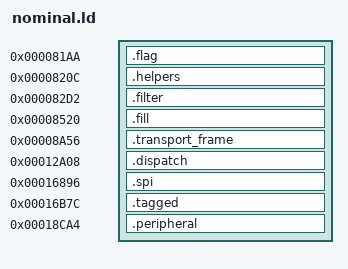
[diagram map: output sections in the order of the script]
OUTPUT_ARCH(riscv)
ENTRY(tsl9_queue_external_82d2)
SECTIONS {
  .flag 0x81aa : ALIGN(2) {
    KEEP(*(.text.tsl9_queue_external_81aa))
  }
  .helpers 0x820c : ALIGN(2) {
    KEEP(*(.text.tsl9_queue_external_820c))
    KEEP(*(.text.tsl9_dispatch_external_821e))
  }
  .filter 0x82d2 : ALIGN(2) {
    KEEP(*(.text.tsl9_queue_external_82d2))
    KEEP(*(.text.tsl9_filter_scan_8308))
    KEEP(*(.text.tsl9_filter_pack_8328))
    KEEP(*(.text.tsl9_filter_emit_8358))
    KEEP(*(.text.tsl9_filter_test_836a))
    KEEP(*(.text.tsl9_filter_finish_836e))
    KEEP(*(.text.tsl9_filter_second_838a))
  }
  .fill 0x8520 : ALIGN(2) {
    KEEP(*(.text.tsl9_tagged_external_8520))
    KEEP(*(.text.tsl9_fill_alignment_8528))
    KEEP(*(.text.tsl9_fill_pattern_guard_852e))
    KEEP(*(.text.tsl9_fill_word_setup_8530))
    KEEP(*(.text.tsl9_fill_words_8538))
    KEEP(*(.text.tsl9_fill_tail_guard_8546))
    KEEP(*(.text.tsl9_fill_word_return_8548))
    KEEP(*(.text.tsl9_fill_tail_dispatch_854a))
    KEEP(*(.text.tsl9_fill_bytes_855a))
    KEEP(*(.text.tsl9_fill_byte_return_8596))
    KEEP(*(.text.tsl9_fill_pattern_8598))
    KEEP(*(.text.tsl9_fill_align_dispatch_85aa))
    KEEP(*(.text.tsl9_fill_align_resume_85ba))
  }
  .transport_frame 0x8a56 : ALIGN(2) {
    KEEP(*(.text.tsl9_filter_external_8a56))
    KEEP(*(.text.tsl9_transport_frame_8a5e))
    KEEP(*(.text.tsl9_transport_first_8a7a))
    KEEP(*(.text.tsl9_transport_first_result_8a90))
    KEEP(*(.text.tsl9_transport_second_8a96))
    KEEP(*(.text.tsl9_transport_second_result_8ab6))
    KEEP(*(.text.tsl9_transport_reject_8abe))
    KEEP(*(.text.tsl9_transport_select0_8acc))
    KEEP(*(.text.tsl9_transport_pack_8ace))
    KEEP(*(.text.tsl9_transport_test_8b0a))
    KEEP(*(.text.tsl9_transport_finish_8b14))
    KEEP(*(.text.tsl9_transport_copy_8b52))
    KEEP(*(.text.tsl9_transport_bare_return_8b6c))
  }
  .dispatch 0x12a08 : ALIGN(2) {
    KEEP(*(.text.tsl9_queue_external_12a08))
    KEEP(*(.text.tsl9_dispatch_status_12a14))
    KEEP(*(.text.tsl9_dispatch_ID_12a16))
    KEEP(*(.text.tsl9_dispatch_query_12a20))
    KEEP(*(.text.tsl9_dispatch_tag_12a28))
    KEEP(*(.text.tsl9_dispatch_copy_12a2e))
    KEEP(*(.text.tsl9_dispatch_peripheral_12a50))
    KEEP(*(.text.tsl9_dispatch_finish_12a5e))
    KEEP(*(.text.tsl9_dispatch_tagged_12a66))
  }
  .spi 0x16896 : ALIGN(2) {
    KEEP(*(.text.tsl9_spi_transfer_entry_16896))
    KEEP(*(.text.tsl9_spi_tx_poll_1689e))
    KEEP(*(.text.tsl9_spi_tx_ready_168a6))
    KEEP(*(.text.tsl9_spi_rx_poll_168b6))
    KEEP(*(.text.tsl9_spi_rx_done_168be))
    KEEP(*(.text.tsl9_spi_tx_wait_168c8))
    KEEP(*(.text.tsl9_spi_timeout_168d0))
    KEEP(*(.text.tsl9_spi_rx_wait_168d4))
    KEEP(*(.text.tsl9_tagged_external_168de))
    KEEP(*(.text.tsl9_spi_write_guard1_168e6))
    KEEP(*(.text.tsl9_spi_write_select1_168f0))
    KEEP(*(.text.tsl9_spi_write_guard2_168fa))
    KEEP(*(.text.tsl9_spi_write_select2_168fe))
    KEEP(*(.text.tsl9_spi_write_command_16908))
    KEEP(*(.text.tsl9_spi_write_address_16910))
    KEEP(*(.text.tsl9_spi_write_test_1691a))
    KEEP(*(.text.tsl9_spi_write_finish_1691e))
    KEEP(*(.text.tsl9_spi_write_payload_16932))
    KEEP(*(.text.tsl9_tagged_external_1693e))
    KEEP(*(.text.tsl9_spi_modify_guard1_16942))
    KEEP(*(.text.tsl9_spi_modify_select1_16948))
    KEEP(*(.text.tsl9_spi_modify_guard2_16952))
    KEEP(*(.text.tsl9_spi_modify_select2_16956))
    KEEP(*(.text.tsl9_spi_modify_command_16960))
    KEEP(*(.text.tsl9_spi_modify_address_1696c))
    KEEP(*(.text.tsl9_spi_modify_mask_16974))
    KEEP(*(.text.tsl9_spi_modify_value_1697c))
    KEEP(*(.text.tsl9_spi_modify_finish_16984))
    KEEP(*(.text.tsl9_register_read_entry_16994))
    KEEP(*(.text.tsl9_register_read_body))
  }
  .tagged 0x16b7c : ALIGN(2) {
    KEEP(*(.text.tsl9_dispatch_external_16b7c))
    KEEP(*(.text.tsl9_tagged_config_16b8c))
    KEEP(*(.text.tsl9_tagged_frame_16b9c))
    KEEP(*(.text.tsl9_tagged_length_16ba8))
    KEEP(*(.text.tsl9_tagged_header_16bb2))
    KEEP(*(.text.tsl9_tagged_payload_16bd2))
    KEEP(*(.text.tsl9_tagged_loop_setup_16bfa))
    KEEP(*(.text.tsl9_tagged_loop_16bfe))
    KEEP(*(.text.tsl9_tagged_send_16c14))
    KEEP(*(.text.tsl9_tagged_request_16c30))
    KEEP(*(.text.tsl9_tagged_status_16c3e))
    KEEP(*(.text.tsl9_tagged_finish_16c52))
    KEEP(*(.text.tsl9_tagged_busy_16c62))
    KEEP(*(.text.tsl9_tagged_invalid_16c6c))
    KEEP(*(.text.tsl9_tagged_early_16c6e))
  }
  .peripheral 0x18ca4 : ALIGN(2) {
    KEEP(*(.text.tsl9_dispatch_external_18ca4))
    KEEP(*(.text.tsl9_peripheral_selected_18cc6))
    KEEP(*(.text.tsl9_peripheral_metadata_18cec))
    KEEP(*(.text.tsl9_peripheral_finish_18d5a))
    KEEP(*(.text.tsl9_peripheral_select0_18d5e))
    KEEP(*(.text.tsl9_peripheral_select1_18d62))
    KEEP(*(.text.tsl9_peripheral_alternate_18d66))
  }
  /DISCARD/ : { *(.comment) *(.note*) *(.riscv.attributes) }
  ASSERT(SIZEOF(.flag) == 6, "Owned original flag extent")
  ASSERT(SIZEOF(.helpers) == 60, "Owned original helpers extent")
  ASSERT(SIZEOF(.filter) == 188, "Owned original filter extent")
  ASSERT(SIZEOF(.fill) == 168, "Owned original fill extent")
  ASSERT(SIZEOF(.transport_frame) == 280, "Owned original transport_frame extent")
  ASSERT(SIZEOF(.dispatch) == 102, "Owned original dispatch extent")
  ASSERT(SIZEOF(.spi) == 326, "Owned original spi extent")
  ASSERT(SIZEOF(.tagged) == 246, "Owned original tagged extent")
  ASSERT(SIZEOF(.peripheral) == 212, "Owned original peripheral extent")
  ASSERT(tsl9_queue_external_81aa == 0x81aa, "Original PC tsl9_queue_external_81aa")
  ASSERT(tsl9_queue_external_820c == 0x820c, "Original PC tsl9_queue_external_820c")
  ASSERT(tsl9_dispatch_external_821e == 0x821e, "Original PC tsl9_dispatch_external_821e")
  ASSERT(tsl9_queue_external_82d2 == 0x82d2, "Original PC tsl9_queue_external_82d2")
  ASSERT(tsl9_filter_scan_8308 == 0x8308, "Original PC tsl9_filter_scan_8308")
  ASSERT(tsl9_filter_pack_8328 == 0x8328, "Original PC tsl9_filter_pack_8328")
  ASSERT(tsl9_filter_emit_8358 == 0x8358, "Original PC tsl9_filter_emit_8358")
  ASSERT(tsl9_filter_test_836a == 0x836a, "Original PC tsl9_filter_test_836a")
  ASSERT(tsl9_filter_finish_836e == 0x836e, "Original PC tsl9_filter_finish_836e")
  ASSERT(tsl9_filter_second_838a == 0x838a, "Original PC tsl9_filter_second_838a")
  ASSERT(tsl9_tagged_external_8520 == 0x8520, "Original PC tsl9_tagged_external_8520")
  ASSERT(tsl9_fill_alignment_8528 == 0x8528, "Original PC tsl9_fill_alignment_8528")
  ASSERT(tsl9_fill_pattern_guard_852e == 0x852e, "Original PC tsl9_fill_pattern_guard_852e")
  ASSERT(tsl9_fill_word_setup_8530 == 0x8530, "Original PC tsl9_fill_word_setup_8530")
  ASSERT(tsl9_fill_words_8538 == 0x8538, "Original PC tsl9_fill_words_8538")
  ASSERT(tsl9_fill_tail_guard_8546 == 0x8546, "Original PC tsl9_fill_tail_guard_8546")
  ASSERT(tsl9_fill_word_return_8548 == 0x8548, "Original PC tsl9_fill_word_return_8548")
  ASSERT(tsl9_fill_tail_dispatch_854a == 0x854a, "Original PC tsl9_fill_tail_dispatch_854a")
  ASSERT(tsl9_fill_bytes_855a == 0x855a, "Original PC tsl9_fill_bytes_855a")
  ASSERT(tsl9_fill_byte_return_8596 == 0x8596, "Original PC tsl9_fill_byte_return_8596")
  ASSERT(tsl9_fill_pattern_8598 == 0x8598, "Original PC tsl9_fill_pattern_8598")
  ASSERT(tsl9_fill_align_dispatch_85aa == 0x85aa, "Original PC tsl9_fill_align_dispatch_85aa")
  ASSERT(tsl9_fill_align_resume_85ba == 0x85ba, "Original PC tsl9_fill_align_resume_85ba")
  ASSERT(tsl9_filter_external_8a56 == 0x8a56, "Original PC tsl9_filter_external_8a56")
  ASSERT(tsl9_transport_frame_8a5e == 0x8a5e, "Original PC tsl9_transport_frame_8a5e")
  ASSERT(tsl9_transport_first_8a7a == 0x8a7a, "Original PC tsl9_transport_first_8a7a")
  ASSERT(tsl9_transport_first_result_8a90 == 0x8a90, "Original PC tsl9_transport_first_result_8a90")
  ASSERT(tsl9_transport_second_8a96 == 0x8a96, "Original PC tsl9_transport_second_8a96")
  ASSERT(tsl9_transport_second_result_8ab6 == 0x8ab6, "Original PC tsl9_transport_second_result_8ab6")
  ASSERT(tsl9_transport_reject_8abe == 0x8abe, "Original PC tsl9_transport_reject_8abe")
  ASSERT(tsl9_transport_select0_8acc == 0x8acc, "Original PC tsl9_transport_select0_8acc")
  ASSERT(tsl9_transport_pack_8ace == 0x8ace, "Original PC tsl9_transport_pack_8ace")
  ASSERT(tsl9_transport_test_8b0a == 0x8b0a, "Original PC tsl9_transport_test_8b0a")
  ASSERT(tsl9_transport_finish_8b14 == 0x8b14, "Original PC tsl9_transport_finish_8b14")
  ASSERT(tsl9_transport_copy_8b52 == 0x8b52, "Original PC tsl9_transport_copy_8b52")
  ASSERT(tsl9_transport_bare_return_8b6c == 0x8b6c, "Original PC tsl9_transport_bare_return_8b6c")
  ASSERT(tsl9_queue_external_12a08 == 0x12a08, "Original PC tsl9_queue_external_12a08")
  ASSERT(tsl9_dispatch_status_12a14 == 0x12a14, "Original PC tsl9_dispatch_status_12a14")
  ASSERT(tsl9_dispatch_ID_12a16 == 0x12a16, "Original PC tsl9_dispatch_ID_12a16")
  ASSERT(tsl9_dispatch_query_12a20 == 0x12a20, "Original PC tsl9_dispatch_query_12a20")
  ASSERT(tsl9_dispatch_tag_12a28 == 0x12a28, "Original PC tsl9_dispatch_tag_12a28")
  ASSERT(tsl9_dispatch_copy_12a2e == 0x12a2e, "Original PC tsl9_dispatch_copy_12a2e")
  ASSERT(tsl9_dispatch_peripheral_12a50 == 0x12a50, "Original PC tsl9_dispatch_peripheral_12a50")
  ASSERT(tsl9_dispatch_finish_12a5e == 0x12a5e, "Original PC tsl9_dispatch_finish_12a5e")
  ASSERT(tsl9_dispatch_tagged_12a66 == 0x12a66, "Original PC tsl9_dispatch_tagged_12a66")
  ASSERT(tsl9_spi_transfer_entry_16896 == 0x16896, "Original PC tsl9_spi_transfer_entry_16896")
  ASSERT(tsl9_spi_tx_poll_1689e == 0x1689e, "Original PC tsl9_spi_tx_poll_1689e")
  ASSERT(tsl9_spi_tx_ready_168a6 == 0x168a6, "Original PC tsl9_spi_tx_ready_168a6")
  ASSERT(tsl9_spi_rx_poll_168b6 == 0x168b6, "Original PC tsl9_spi_rx_poll_168b6")
  ASSERT(tsl9_spi_rx_done_168be == 0x168be, "Original PC tsl9_spi_rx_done_168be")
  ASSERT(tsl9_spi_tx_wait_168c8 == 0x168c8, "Original PC tsl9_spi_tx_wait_168c8")
  ASSERT(tsl9_spi_timeout_168d0 == 0x168d0, "Original PC tsl9_spi_timeout_168d0")
  ASSERT(tsl9_spi_rx_wait_168d4 == 0x168d4, "Original PC tsl9_spi_rx_wait_168d4")
  ASSERT(tsl9_tagged_external_168de == 0x168de, "Original PC tsl9_tagged_external_168de")
  ASSERT(tsl9_spi_write_guard1_168e6 == 0x168e6, "Original PC tsl9_spi_write_guard1_168e6")
  ASSERT(tsl9_spi_write_select1_168f0 == 0x168f0, "Original PC tsl9_spi_write_select1_168f0")
  ASSERT(tsl9_spi_write_guard2_168fa == 0x168fa, "Original PC tsl9_spi_write_guard2_168fa")
  ASSERT(tsl9_spi_write_select2_168fe == 0x168fe, "Original PC tsl9_spi_write_select2_168fe")
  ASSERT(tsl9_spi_write_command_16908 == 0x16908, "Original PC tsl9_spi_write_command_16908")
  ASSERT(tsl9_spi_write_address_16910 == 0x16910, "Original PC tsl9_spi_write_address_16910")
  ASSERT(tsl9_spi_write_test_1691a == 0x1691a, "Original PC tsl9_spi_write_test_1691a")
  ASSERT(tsl9_spi_write_finish_1691e == 0x1691e, "Original PC tsl9_spi_write_finish_1691e")
  ASSERT(tsl9_spi_write_payload_16932 == 0x16932, "Original PC tsl9_spi_write_payload_16932")
  ASSERT(tsl9_tagged_external_1693e == 0x1693e, "Original PC tsl9_tagged_external_1693e")
  ASSERT(tsl9_spi_modify_guard1_16942 == 0x16942, "Original PC tsl9_spi_modify_guard1_16942")
  ASSERT(tsl9_spi_modify_select1_16948 == 0x16948, "Original PC tsl9_spi_modify_select1_16948")
  ASSERT(tsl9_spi_modify_guard2_16952 == 0x16952, "Original PC tsl9_spi_modify_guard2_16952")
  ASSERT(tsl9_spi_modify_select2_16956 == 0x16956, "Original PC tsl9_spi_modify_select2_16956")
  ASSERT(tsl9_spi_modify_command_16960 == 0x16960, "Original PC tsl9_spi_modify_command_16960")
  ASSERT(tsl9_spi_modify_address_1696c == 0x1696c, "Original PC tsl9_spi_modify_address_1696c")
  ASSERT(tsl9_spi_modify_mask_16974 == 0x16974, "Original PC tsl9_spi_modify_mask_16974")
  ASSERT(tsl9_spi_modify_value_1697c == 0x1697c, "Original PC tsl9_spi_modify_value_1697c")
  ASSERT(tsl9_spi_modify_finish_16984 == 0x16984, "Original PC tsl9_spi_modify_finish_16984")
  ASSERT(tsl9_register_read_entry_16994 == 0x16994, "Original PC tsl9_register_read_entry_16994")
  ASSERT(tsl9_register_read_body == 0x16998, "Original PC tsl9_register_read_body")
  ASSERT(tsl9_dispatch_external_16b7c == 0x16b7c, "Original PC tsl9_dispatch_external_16b7c")
  ASSERT(tsl9_tagged_config_16b8c == 0x16b8c, "Original PC tsl9_tagged_config_16b8c")
  ASSERT(tsl9_tagged_frame_16b9c == 0x16b9c, "Original PC tsl9_tagged_frame_16b9c")
  ASSERT(tsl9_tagged_length_16ba8 == 0x16ba8, "Original PC tsl9_tagged_length_16ba8")
  ASSERT(tsl9_tagged_header_16bb2 == 0x16bb2, "Original PC tsl9_tagged_header_16bb2")
  ASSERT(tsl9_tagged_payload_16bd2 == 0x16bd2, "Original PC tsl9_tagged_payload_16bd2")
  ASSERT(tsl9_tagged_loop_setup_16bfa == 0x16bfa, "Original PC tsl9_tagged_loop_setup_16bfa")
  ASSERT(tsl9_tagged_loop_16bfe == 0x16bfe, "Original PC tsl9_tagged_loop_16bfe")
  ASSERT(tsl9_tagged_send_16c14 == 0x16c14, "Original PC tsl9_tagged_send_16c14")
  ASSERT(tsl9_tagged_request_16c30 == 0x16c30, "Original PC tsl9_tagged_request_16c30")
  ASSERT(tsl9_tagged_status_16c3e == 0x16c3e, "Original PC tsl9_tagged_status_16c3e")
  ASSERT(tsl9_tagged_finish_16c52 == 0x16c52, "Original PC tsl9_tagged_finish_16c52")
  ASSERT(tsl9_tagged_busy_16c62 == 0x16c62, "Original PC tsl9_tagged_busy_16c62")
  ASSERT(tsl9_tagged_invalid_16c6c == 0x16c6c, "Original PC tsl9_tagged_invalid_16c6c")
  ASSERT(tsl9_tagged_early_16c6e == 0x16c6e, "Original PC tsl9_tagged_early_16c6e")
  ASSERT(tsl9_dispatch_external_18ca4 == 0x18ca4, "Original PC tsl9_dispatch_external_18ca4")
  ASSERT(tsl9_peripheral_selected_18cc6 == 0x18cc6, "Original PC tsl9_peripheral_selected_18cc6")
  ASSERT(tsl9_peripheral_metadata_18cec == 0x18cec, "Original PC tsl9_peripheral_metadata_18cec")
  ASSERT(tsl9_peripheral_finish_18d5a == 0x18d5a, "Original PC tsl9_peripheral_finish_18d5a")
  ASSERT(tsl9_peripheral_select0_18d5e == 0x18d5e, "Original PC tsl9_peripheral_select0_18d5e")
  ASSERT(tsl9_peripheral_select1_18d62 == 0x18d62, "Original PC tsl9_peripheral_select1_18d62")
  ASSERT(tsl9_peripheral_alternate_18d66 == 0x18d66, "Original PC tsl9_peripheral_alternate_18d66")
}
